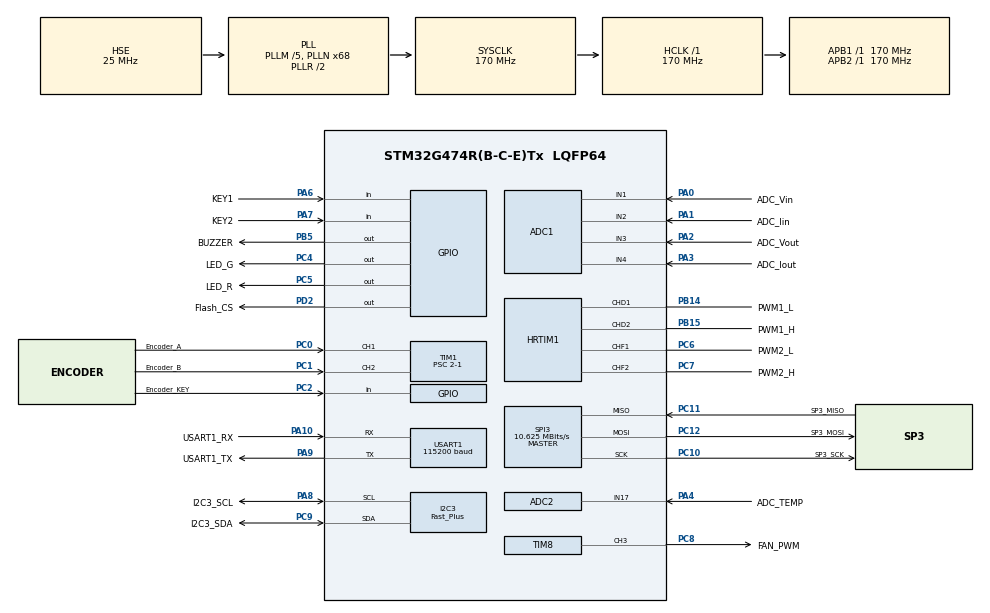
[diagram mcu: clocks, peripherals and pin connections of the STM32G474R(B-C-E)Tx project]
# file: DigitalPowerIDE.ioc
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ADC1.Channel-0\#ChannelRegularConversion=ADC_CHANNEL_1
ADC1.Channel-1\#ChannelRegularConversion=ADC_CHANNEL_2
ADC1.Channel-2\#ChannelRegularConversion=ADC_CHANNEL_3
ADC1.Channel-3\#ChannelRegularConversion=ADC_CHANNEL_4
ADC1.ClockPrescaler=ADC_CLOCK_SYNC_PCLK_DIV4
ADC1.ContinuousConvMode=DISABLE
ADC1.DMAContinuousRequests=ENABLE
ADC1.EOCSelection=ADC_EOC_SEQ_CONV
ADC1.ExternalTrigConv=ADC_EXTERNALTRIG_HRTIM_TRG1
ADC1.LowPowerAutoWait=DISABLE
ADC1.Mode=ADC_MODE_INDEPENDENT
ADC1.NbrOfConversion=4
ADC1.NbrOfConversionFlag=1
ADC1.OffsetNumber-0\#ChannelRegularConversion=ADC_OFFSET_NONE
ADC1.OffsetNumber-1\#ChannelRegularConversion=ADC_OFFSET_NONE
ADC1.OffsetNumber-2\#ChannelRegularConversion=ADC_OFFSET_NONE
ADC1.OffsetNumber-3\#ChannelRegularConversion=ADC_OFFSET_NONE
ADC1.Overrun=ADC_OVR_DATA_OVERWRITTEN
ADC1.OversamplingMode=ENABLE
ADC1.Rank-0\#ChannelRegularConversion=1
ADC1.Rank-1\#ChannelRegularConversion=2
ADC1.Rank-2\#ChannelRegularConversion=3
ADC1.Rank-3\#ChannelRegularConversion=4
ADC1.Ratio=ADC_OVERSAMPLING_RATIO_4
ADC1.RightBitShift=ADC_RIGHTBITSHIFT_1
ADC1.SamplingTime-0\#ChannelRegularConversion=ADC_SAMPLETIME_2CYCLES_5
ADC1.SamplingTime-1\#ChannelRegularConversion=ADC_SAMPLETIME_2CYCLES_5
ADC1.SamplingTime-2\#ChannelRegularConversion=ADC_SAMPLETIME_2CYCLES_5
ADC1.SamplingTime-3\#ChannelRegularConversion=ADC_SAMPLETIME_2CYCLES_5
ADC1.master=1
ADC2.Channel-0\#ChannelRegularConversion=ADC_CHANNEL_17
ADC2.NbrOfConversionFlag=1
ADC2.OffsetNumber-0\#ChannelRegularConversion=ADC_OFFSET_NONE
ADC2.Overrun=ADC_OVR_DATA_OVERWRITTEN
ADC2.OversamplingMode=ENABLE
ADC2.Rank-0\#ChannelRegularConversion=1
ADC2.Ratio=ADC_OVERSAMPLING_RATIO_256
ADC2.RightBitShift=ADC_RIGHTBITSHIFT_4
ADC2.SamplingTime-0\#ChannelRegularConversion=ADC_SAMPLETIME_92CYCLES_5
ADC5.Channel-0\#ChannelRegularConversion=ADC_CHANNEL_TEMPSENSOR_ADC5
ADC5.NbrOfConversionFlag=1
ADC5.OffsetNumber-0\#ChannelRegularConversion=ADC_OFFSET_NONE
ADC5.Overrun=ADC_OVR_DATA_OVERWRITTEN
ADC5.OversamplingMode=ENABLE
ADC5.Rank-0\#ChannelRegularConversion=1
ADC5.Ratio=ADC_OVERSAMPLING_RATIO_64
ADC5.RightBitShift=ADC_RIGHTBITSHIFT_3
ADC5.SamplingTime-0\#ChannelRegularConversion=ADC_SAMPLETIME_640CYCLES_5
Dma.ADC1.0.Direction=DMA_PERIPH_TO_MEMORY
Dma.ADC1.0.EventEnable=DISABLE
Dma.ADC1.0.Instance=DMA1_Channel1
Dma.ADC1.0.MemDataAlignment=DMA_MDATAALIGN_HALFWORD
Dma.ADC1.0.MemInc=DMA_MINC_ENABLE
Dma.ADC1.0.Mode=DMA_CIRCULAR
Dma.ADC1.0.PeriphDataAlignment=DMA_PDATAALIGN_HALFWORD
Dma.ADC1.0.PeriphInc=DMA_PINC_DISABLE
Dma.ADC1.0.Polarity=HAL_DMAMUX_REQ_GEN_RISING
Dma.ADC1.0.Priority=DMA_PRIORITY_HIGH
Dma.ADC1.0.RequestNumber=1
Dma.ADC1.0.SignalID=NONE
Dma.ADC1.0.SyncEnable=DISABLE
Dma.ADC1.0.SyncPolarity=HAL_DMAMUX_SYNC_NO_EVENT
Dma.ADC1.0.SyncRequestNumber=1
Dma.ADC1.0.SyncSignalID=NONE
Dma.Request0=ADC1
Dma.Request1=USART1_TX
Dma.Request2=USART1_RX
Dma.USART1_RX.2.Direction=DMA_PERIPH_TO_MEMORY
Dma.USART1_RX.2.EventEnable=DISABLE
Dma.USART1_RX.2.Instance=DMA1_Channel3
Dma.USART1_RX.2.MemDataAlignment=DMA_MDATAALIGN_BYTE
Dma.USART1_RX.2.MemInc=DMA_MINC_ENABLE
Dma.USART1_RX.2.Mode=DMA_NORMAL
Dma.USART1_RX.2.PeriphDataAlignment=DMA_PDATAALIGN_BYTE
Dma.USART1_RX.2.PeriphInc=DMA_PINC_DISABLE
Dma.USART1_RX.2.Polarity=HAL_DMAMUX_REQ_GEN_RISING
Dma.USART1_RX.2.Priority=DMA_PRIORITY_MEDIUM
Dma.USART1_RX.2.RequestNumber=1
Dma.USART1_RX.2.SignalID=NONE
Dma.USART1_RX.2.SyncEnable=DISABLE
Dma.USART1_RX.2.SyncPolarity=HAL_DMAMUX_SYNC_NO_EVENT
Dma.USART1_RX.2.SyncRequestNumber=1
Dma.USART1_RX.2.SyncSignalID=NONE
Dma.USART1_TX.1.Direction=DMA_MEMORY_TO_PERIPH
Dma.USART1_TX.1.EventEnable=DISABLE
Dma.USART1_TX.1.Instance=DMA1_Channel2
Dma.USART1_TX.1.MemDataAlignment=DMA_MDATAALIGN_BYTE
Dma.USART1_TX.1.MemInc=DMA_MINC_ENABLE
Dma.USART1_TX.1.Mode=DMA_NORMAL
Dma.USART1_TX.1.PeriphDataAlignment=DMA_PDATAALIGN_BYTE
Dma.USART1_TX.1.PeriphInc=DMA_PINC_DISABLE
Dma.USART1_TX.1.Polarity=HAL_DMAMUX_REQ_GEN_RISING
Dma.USART1_TX.1.Priority=DMA_PRIORITY_MEDIUM
Dma.USART1_TX.1.RequestNumber=1
Dma.USART1_TX.1.SignalID=NONE
Dma.USART1_TX.1.SyncEnable=DISABLE
Dma.USART1_TX.1.SyncPolarity=HAL_DMAMUX_SYNC_NO_EVENT
Dma.USART1_TX.1.SyncRequestNumber=1
Dma.USART1_TX.1.SyncSignalID=NONE
HRTIM1.ADCTrigger1_Source1=HRTIM_ADCTRIGGEREVENT13_TIMERD_CMP3
HRTIM1.ADCTrigger_Id1=HRTIM_ADCTRIGGER_1
HRTIM1.CompareUnit1-Output_TD1TD2=HRTIM_COMPAREUNIT_1
HRTIM1.CompareUnit1-Output_TF1TF2=HRTIM_COMPAREUNIT_1
HRTIM1.CompareUnit3-Output_TD1TD2=HRTIM_COMPAREUNIT_3
HRTIM1.CompareValue1-Output_TD1TD2=15000
HRTIM1.CompareValue1-Output_TF1TF2=300
HRTIM1.CompareValue3-Output_TD1TD2=7500
HRTIM1.DeadTimeInsertion-Output_TD1TD2=HRTIM_TIMDEADTIMEINSERTION_ENABLED
HRTIM1.DeadTimeInsertion-Output_TF1TF2=HRTIM_TIMDEADTIMEINSERTION_ENABLED
HRTIM1.FallingLock-Output_TD1TD2=HRTIM_TIMDEADTIME_FALLINGLOCK_READONLY
HRTIM1.FallingLock-Output_TF1TF2=HRTIM_TIMDEADTIME_FALLINGLOCK_READONLY
HRTIM1.FallingSignLock-Output_TD1TD2=HRTIM_TIMDEADTIME_FALLINGSIGNLOCK_READONLY
HRTIM1.FallingSignLock-Output_TF1TF2=HRTIM_TIMDEADTIME_FALLINGSIGNLOCK_READONLY
HRTIM1.FallingValue-Output_TD1TD2=100
HRTIM1.FallingValue-Output_TF1TF2=100
HRTIM1.FaultLock-Output_TD1TD2=HRTIM_TIMFAULTLOCK_READONLY
HRTIM1.FaultLock-Output_TF1TF2=HRTIM_TIMFAULTLOCK_READONLY
HRTIM1.GreaterCMP1_TF=HRTIM_TIMERGTCMP1_EQUAL
HRTIM1.InterruptRequests1-Output_TD1TD2=HRTIM_TIM_IT_REP
HRTIM1.NumberADCTriggerSource1=1
HRTIM1.NumberInterruptRequests-Output_TD1TD2=1
HRTIM1.NumberResetSource1-Output_TD1TD2=1
HRTIM1.NumberResetSource1-Output_TF1TF2=1
HRTIM1.NumberSetSource1-Output_TD1TD2=1
HRTIM1.NumberSetSource1-Output_TF1TF2=1
HRTIM1.Periode_TD=30000
HRTIM1.Periode_TF=30000
HRTIM1.PreloadEnable-Output_TD1TD2=HRTIM_PRELOAD_ENABLED
HRTIM1.PreloadEnable-Output_TF1TF2=HRTIM_PRELOAD_ENABLED
HRTIM1.PrescalerRatio_TF=HRTIM_PRESCALERRATIO_MUL32
HRTIM1.RepetitionCounter-Output_TD1TD2=0
HRTIM1.RepetitionUpdate-Output_TD1TD2=HRTIM_UPDATEONREPETITION_ENABLED
HRTIM1.RepetitionUpdate-Output_TF1TF2=HRTIM_UPDATEONREPETITION_ENABLED
HRTIM1.ResetOutput1_Source1-Output_TD1TD2=HRTIM_OUTPUTRESET_TIMCMP1
HRTIM1.ResetOutput1_Source1-Output_TF1TF2=HRTIM_OUTPUTRESET_TIMCMP1
HRTIM1.RisingLock-Output_TD1TD2=HRTIM_TIMDEADTIME_RISINGLOCK_READONLY
HRTIM1.RisingLock-Output_TF1TF2=HRTIM_TIMDEADTIME_RISINGLOCK_READONLY
HRTIM1.RisingSignLock-Output_TD1TD2=HRTIM_TIMDEADTIME_RISINGSIGNLOCK_READONLY
HRTIM1.RisingSignLock-Output_TF1TF2=HRTIM_TIMDEADTIME_RISINGSIGNLOCK_READONLY
HRTIM1.RisingValue-Output_TD1TD2=100
HRTIM1.RisingValue-Output_TF1TF2=100
HRTIM1.SetOutput1_Source1-Output_TD1TD2=HRTIM_OUTPUTSET_TIMPER
HRTIM1.SetOutput1_Source1-Output_TF1TF2=HRTIM_OUTPUTSET_TIMPER
I2C3.CustomTiming=Disabled
I2C3.I2C_Speed_Mode=I2C_Fast_Plus
I2C3.Timing=0x4052060F
IWDG.Prescaler=IWDG_PRESCALER_32
IWDG.Reload=1000
IWDG.Window=1000
Mcu.Family=STM32G4
Mcu.Name=STM32G474R(B-C-E)Tx
Mcu.Package=LQFP64
NVIC.DMA1_Channel1_IRQn=true\:5\:0\:true\:false\:true\:false\:true\:true
NVIC.DMA1_Channel2_IRQn=true\:5\:0\:true\:false\:true\:false\:true\:true
NVIC.DMA1_Channel3_IRQn=true\:5\:0\:true\:false\:true\:false\:true\:true
NVIC.HRTIM1_TIMD_IRQn=true\:1\:0\:true\:false\:true\:true\:true\:true
NVIC.PriorityGroup=NVIC_PRIORITYGROUP_4
NVIC.TIM2_IRQn=true\:1\:0\:true\:false\:true\:true\:true\:true
NVIC.TIM3_IRQn=true\:2\:0\:true\:false\:true\:true\:true\:true
NVIC.TIM4_IRQn=true\:3\:0\:true\:false\:true\:true\:true\:true
NVIC.USART1_IRQn=true\:5\:0\:true\:false\:true\:true\:true\:true
PA0.GPIO_Label=ADC_Vin
PA0.Mode=IN1-Single-Ended
PA0.Signal=ADC1_IN1
PA1.GPIO_Label=ADC_Iin
PA1.Mode=IN2-Single-Ended
PA1.Signal=ADC1_IN2
PA10.GPIO_Label=USART1_RX
PA10.GPIO_Speed=GPIO_SPEED_FREQ_VERY_HIGH
PA10.Mode=Asynchronous
PA10.Signal=USART1_RX
PA13.Mode=Serial_Wire
PA13.Signal=SYS_JTMS-SWDIO
PA14.Mode=Serial_Wire
PA14.Signal=SYS_JTCK-SWCLK
PA2.GPIO_Label=ADC_Vout
PA2.Mode=IN3-Single-Ended
PA2.Signal=ADC1_IN3
PA3.GPIO_Label=ADC_Iout
PA3.Mode=IN4-Single-Ended
PA3.Signal=ADC1_IN4
PA4.GPIO_Label=ADC_TEMP
PA4.Mode=IN17-Single-Ended
PA4.Signal=ADC2_IN17
PA6.GPIO_Label=KEY1
PA6.Signal=GPIO_Input
PA7.GPIO_Label=KEY2
PA7.Signal=GPIO_Input
PA8.GPIO_Label=I2C3_SCL
PA8.GPIO_Pu=GPIO_PULLUP
PA8.GPIO_Speed=GPIO_SPEED_FREQ_VERY_HIGH
PA8.Mode=I2C
PA8.Signal=I2C3_SCL
PA9.GPIO_Label=USART1_TX
PA9.GPIO_Speed=GPIO_SPEED_FREQ_VERY_HIGH
PA9.Mode=Asynchronous
PA9.Signal=USART1_TX
PB14.GPIO_Label=PWM1_L
PB14.Mode=Output_TD1TD2
PB14.Signal=HRTIM1_CHD1
PB15.GPIO_Label=PWM1_H
PB15.Mode=Output_TD1TD2
PB15.Signal=HRTIM1_CHD2
PB5.GPIO_Label=BUZZER
PB5.GPIO_Speed=GPIO_SPEED_FREQ_MEDIUM
PB5.PinState=GPIO_PIN_SET
PB5.Signal=GPIO_Output
PC0.GPIO_Label=Encoder_A
PC0.Signal=S_TIM1_CH1
PC1.GPIO_Label=Encoder_B
PC1.Signal=S_TIM1_CH2
PC10.GPIO_Label=SP3_SCK
PC10.GPIO_Speed=GPIO_SPEED_FREQ_VERY_HIGH
PC10.Mode=Full_Duplex_Master
PC10.Signal=SPI3_SCK
PC11.GPIO_Label=SP3_MISO
PC11.GPIO_Speed=GPIO_SPEED_FREQ_VERY_HIGH
PC11.Mode=Full_Duplex_Master
PC11.Signal=SPI3_MISO
PC12.GPIO_Label=SP3_MOSI
PC12.GPIO_Speed=GPIO_SPEED_FREQ_VERY_HIGH
PC12.Mode=Full_Duplex_Master
PC12.Signal=SPI3_MOSI
PC14-OSC32_IN.Mode=LSE-External-Oscillator
PC14-OSC32_IN.Signal=RCC_OSC32_IN
PC15-OSC32_OUT.Mode=LSE-External-Oscillator
PC15-OSC32_OUT.Signal=RCC_OSC32_OUT
PC2.GPIO_Label=Encoder_KEY
PC2.Signal=GPIO_Input
PC4.GPIO_Label=LED_G
PC4.GPIO_Speed=GPIO_SPEED_FREQ_MEDIUM
PC4.PinState=GPIO_PIN_SET
PC4.Signal=GPIO_Output
PC5.GPIO_Label=LED_R
PC5.GPIO_ModeDefaultOutputPP=GPIO_MODE_OUTPUT_PP
PC5.GPIO_Speed=GPIO_SPEED_FREQ_MEDIUM
PC5.PinState=GPIO_PIN_SET
PC5.Signal=GPIO_Output
PC6.GPIO_Label=PWM2_L
PC6.Mode=Output_TF1TF2
PC6.Signal=HRTIM1_CHF1
PC7.GPIO_Label=PWM2_H
PC7.Mode=Output_TF1TF2
PC7.Signal=HRTIM1_CHF2
PC8.GPIO_Label=FAN_PWM
PC8.GPIO_Speed=GPIO_SPEED_FREQ_VERY_HIGH
PC8.Signal=S_TIM8_CH3
PC9.GPIO_Label=I2C3_SDA
PC9.GPIO_Pu=GPIO_PULLUP
PC9.GPIO_Speed=GPIO_SPEED_FREQ_VERY_HIGH
PC9.Mode=I2C
PC9.Signal=I2C3_SDA
PD2.GPIO_Label=Flash_CS
PD2.GPIO_Speed=GPIO_SPEED_FREQ_VERY_HIGH
PD2.PinState=GPIO_PIN_SET
PD2.Signal=GPIO_Output
PF0-OSC_IN.Mode=HSE-External-Oscillator
PF0-OSC_IN.Signal=RCC_OSC_IN
PF1-OSC_OUT.Mode=HSE-External-Oscillator
PF1-OSC_OUT.Signal=RCC_OSC_OUT
ProjectManager.HeapSize=0x200
ProjectManager.StackSize=0x400
ProjectManager.TargetToolchain=STM32CubeIDE
RCC.ADC12Freq_Value=170000000
RCC.ADC345Freq_Value=170000000
RCC.AHBFreq_Value=170000000
RCC.APB1Freq_Value=170000000
RCC.APB1TimFreq_Value=170000000
RCC.APB2Freq_Value=170000000
RCC.APB2TimFreq_Value=170000000
RCC.CortexFreq_Value=170000000
RCC.EXTERNAL_CLOCK_VALUE=12288000
RCC.EnbaleCSS=true
RCC.HCLKFreq_Value=170000000
RCC.HSE_VALUE=25000000
RCC.HSI48_VALUE=48000000
RCC.HSI_VALUE=16000000
RCC.PLLM=RCC_PLLM_DIV5
RCC.PLLN=68
RCC.PLLSourceVirtual=RCC_PLLSOURCE_HSE
RCC.SYSCLKFreq_VALUE=170000000
RCC.SYSCLKSource=RCC_SYSCLKSOURCE_PLLCLK
RCC.USBFreq_Value=170000000
RCC.VCOOutputFreq_Value=340000000
SH.S_TIM1_CH1.0=TIM1_CH1,Encoder_Interface
SH.S_TIM1_CH2.0=TIM1_CH2,Encoder_Interface
SH.S_TIM8_CH3.0=TIM8_CH3,PWM Generation3 CH3
SPI3.BaudRatePrescaler=SPI_BAUDRATEPRESCALER_16
SPI3.CalculateBaudRate=10.625 MBits/s
SPI3.DataSize=SPI_DATASIZE_8BIT
SPI3.Direction=SPI_DIRECTION_2LINES
SPI3.Mode=SPI_MODE_MASTER
SPI3.VirtualType=VM_MASTER
TIM1.IC2Polarity=TIM_ICPOLARITY_FALLING
TIM1.PeriodNoDither=60000
TIM1.Prescaler=2-1
TIM2.AutoReloadPreload=TIM_AUTORELOAD_PRELOAD_ENABLE
TIM2.PeriodNoDither=10000-1
TIM2.Prescaler=170-1
TIM3.AutoReloadPreload=TIM_AUTORELOAD_PRELOAD_ENABLE
TIM3.PeriodNoDither=5000-1
TIM3.Prescaler=170-1
TIM4.AutoReloadPreload=TIM_AUTORELOAD_PRELOAD_ENABLE
TIM4.PeriodNoDither=10000-1
TIM4.Prescaler=170-1
TIM8.AutoReloadPreload=TIM_AUTORELOAD_PRELOAD_ENABLE
TIM8.Channel-PWM\ Generation3\ CH3=TIM_CHANNEL_3
TIM8.OCFastMode_PWM-PWM\ Generation3\ CH3=TIM_OCFAST_DISABLE
TIM8.PeriodNoDither=1000-1
TIM8.Prescaler=6-1
TIM8.PulseNoDither_3=500
USART1.AutoBaudRateEnableParam=UART_ADVFEATURE_AUTOBAUDRATE_DISABLE
USART1.BaudRate=115200
USART1.VirtualMode-Asynchronous=VM_ASYNC
VP_ADC5_TempSens_Input.Mode=IN-TempSens
VP_IWDG_VS_IWDG.Mode=IWDG_Activate
VP_SYS_VS_DBSignals.Mode=DisableDeadBatterySignals
VP_TIM2_VS_ClockSourceINT.Mode=Internal
VP_TIM3_VS_ClockSourceINT.Mode=Internal
VP_TIM4_VS_ClockSourceINT.Mode=Internal
VP_TIM8_VS_ClockSourceINT.Mode=Internal
board=custom

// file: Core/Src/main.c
/* USER CODE BEGIN Header */
/**
  ******************************************************************************
  * @file           : main.c
  * @brief          : Main program body
  ******************************************************************************
  * @attention
  *
  * Copyright (c) 2026 STMicroelectronics.
  * All rights reserved.
  *
  * This software is licensed under terms that can be found in the LICENSE file
  * in the root directory of this software component.
  * If no LICENSE file comes with this software, it is provided AS-IS.
  *
  ******************************************************************************
  */
/* USER CODE END Header */
#include "main.h"
#include "adc.h"
#include "dma.h"
#include "hrtim.h"
#include "i2c.h"
#include "iwdg.h"
#include "spi.h"
#include "tim.h"
#include "usart.h"
#include "gpio.h"

/* USER CODE BEGIN Includes */
#include "task.h"
/* USER CODE END Includes */

void SystemClock_Config(void);

/* USER CODE BEGIN 0 */
extern Key key1, key2, keyEncoder;
extern int timer;
/* USER CODE END 0 */

int main(void)
{

  /* MCU Configuration--------------------------------------------------------*/

  /* Reset of all peripherals, Initializes the Flash interface and the Systick. */
  HAL_Init();

  /* Configure the system clock */
  SystemClock_Config();

  /* Initialize all configured peripherals */
  MX_GPIO_Init();
  MX_DMA_Init();
  MX_I2C3_Init();
  MX_ADC1_Init();
  MX_ADC2_Init();
  MX_USART1_UART_Init();
  MX_TIM8_Init();
  MX_ADC5_Init();
  MX_HRTIM1_Init();
  MX_TIM3_Init();
  MX_IWDG_Init();
  MX_TIM4_Init();
  MX_SPI3_Init();
  MX_TIM1_Init();
  MX_TIM2_Init();
  /* USER CODE BEGIN 2 */
  taskInit();
  /* USER CODE END 2 */

  /* Infinite loop */
  /* USER CODE BEGIN WHILE */
  while (1)
  {
	  taskRun();
    /* USER CODE END WHILE */

  }
}

void SystemClock_Config(void)
{
  RCC_OscInitTypeDef RCC_OscInitStruct = {0};
  RCC_ClkInitTypeDef RCC_ClkInitStruct = {0};

  /** Configure the main internal regulator output voltage
  */
  HAL_PWREx_ControlVoltageScaling(PWR_REGULATOR_VOLTAGE_SCALE1_BOOST);

  /** Initializes the RCC Oscillators according to the specified parameters
  * in the RCC_OscInitTypeDef structure.
  */
  RCC_OscInitStruct.OscillatorType = RCC_OSCILLATORTYPE_LSI|RCC_OSCILLATORTYPE_HSE;
  RCC_OscInitStruct.HSEState = RCC_HSE_ON;
  RCC_OscInitStruct.LSIState = RCC_LSI_ON;
  RCC_OscInitStruct.PLL.PLLState = RCC_PLL_ON;
  RCC_OscInitStruct.PLL.PLLSource = RCC_PLLSOURCE_HSE;
  RCC_OscInitStruct.PLL.PLLM = RCC_PLLM_DIV5;
  RCC_OscInitStruct.PLL.PLLN = 68;
  RCC_OscInitStruct.PLL.PLLP = RCC_PLLP_DIV2;
  RCC_OscInitStruct.PLL.PLLQ = RCC_PLLQ_DIV2;
  RCC_OscInitStruct.PLL.PLLR = RCC_PLLR_DIV2;
  if (HAL_RCC_OscConfig(&RCC_OscInitStruct) != HAL_OK)
  {
    Error_Handler();
  }

  /** Initializes the CPU, AHB and APB buses clocks
  */
  RCC_ClkInitStruct.ClockType = RCC_CLOCKTYPE_HCLK|RCC_CLOCKTYPE_SYSCLK
                              |RCC_CLOCKTYPE_PCLK1|RCC_CLOCKTYPE_PCLK2;
  RCC_ClkInitStruct.SYSCLKSource = RCC_SYSCLKSOURCE_PLLCLK;
  RCC_ClkInitStruct.AHBCLKDivider = RCC_SYSCLK_DIV1;
  RCC_ClkInitStruct.APB1CLKDivider = RCC_HCLK_DIV1;
  RCC_ClkInitStruct.APB2CLKDivider = RCC_HCLK_DIV1;

  if (HAL_RCC_ClockConfig(&RCC_ClkInitStruct, FLASH_LATENCY_4) != HAL_OK)
  {
    Error_Handler();
  }

  /** Enables the Clock Security System
  */
  HAL_RCC_EnableCSS();
}

/* USER CODE BEGIN 4 */

void HAL_TIM_PeriodElapsedCallback(TIM_HandleTypeDef *htim){
	if(htim->Instance == TIM2){
		timer++;
	}
	if(htim->Instance == TIM3){
		getADCresult();
	}
	if(htim->Instance == TIM4){
		key(&key1);
    	key(&key2);
    	key(&keyEncoder);
	}
}

/* USER CODE END 4 */

void Error_Handler(void)
{
  __disable_irq();
  while (1)
  {
  }
}
